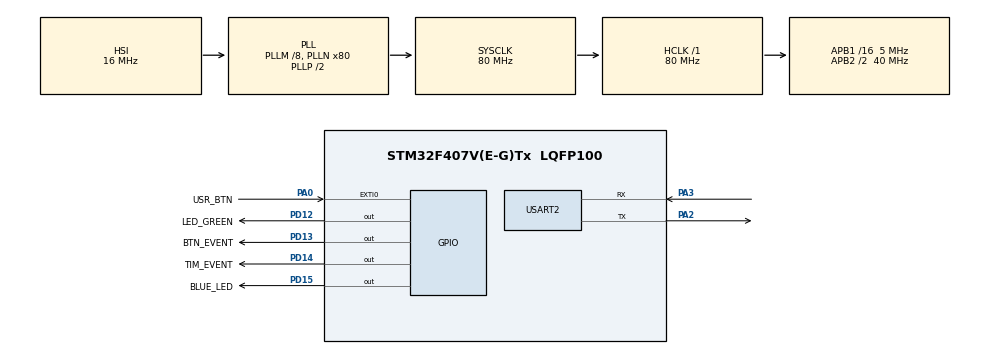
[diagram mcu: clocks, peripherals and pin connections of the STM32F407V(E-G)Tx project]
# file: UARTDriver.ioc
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FREERTOS.Tasks01=defaultTask,0,128,StartDefaultTask,Default,NULL,Dynamic,NULL,NULL
Mcu.Family=STM32F4
Mcu.Name=STM32F407V(E-G)Tx
Mcu.Package=LQFP100
NVIC.EXTI0_IRQn=true\:5\:0\:true\:false\:true\:false\:true\:true\:true
NVIC.PriorityGroup=NVIC_PRIORITYGROUP_4
NVIC.TIM6_DAC_IRQn=true\:5\:0\:false\:false\:true\:true\:true\:true\:true
NVIC.USART2_IRQn=true\:5\:0\:false\:false\:true\:true\:true\:true\:true
PA0-WKUP.GPIO_Label=USR_BTN
PA0-WKUP.Signal=GPXTI0
PA2.Mode=Asynchronous
PA2.Signal=USART2_TX
PA3.Mode=Asynchronous
PA3.Signal=USART2_RX
PD12.GPIO_Label=LED_GREEN
PD12.PinState=GPIO_PIN_SET
PD12.Signal=GPIO_Output
PD13.GPIO_Label=BTN_EVENT
PD13.Signal=GPIO_Output
PD14.GPIO_Label=TIM_EVENT
PD14.Signal=GPIO_Output
PD15.GPIO_Label=BLUE_LED
PD15.Signal=GPIO_Output
ProjectManager.HeapSize=0x200
ProjectManager.StackSize=0x400
ProjectManager.TargetToolchain=Makefile
RCC.48MHZClocksFreq_Value=22857142.85714286
RCC.AHBFreq_Value=80000000
RCC.APB1CLKDivider=RCC_HCLK_DIV16
RCC.APB1Freq_Value=5000000
RCC.APB1TimFreq_Value=10000000
RCC.APB2CLKDivider=RCC_HCLK_DIV2
RCC.APB2Freq_Value=40000000
RCC.APB2TimFreq_Value=80000000
RCC.CortexFreq_Value=80000000
RCC.HCLKFreq_Value=80000000
RCC.HSE_VALUE=8000000
RCC.HSI_VALUE=16000000
RCC.LSE_VALUE=32768
RCC.PLLM=8
RCC.PLLN=80
RCC.PLLQ=7
RCC.SYSCLKFreq_VALUE=80000000
RCC.SYSCLKSource=RCC_SYSCLKSOURCE_PLLCLK
RCC.VCOOutputFreq_Value=160000000
TIM6.AutoReloadPreload=TIM_AUTORELOAD_PRELOAD_ENABLE
TIM6.Period=4999
TIM6.Prescaler=9999
USART2.VirtualMode=VM_ASYNC
VP_FREERTOS_VS_CMSIS_V1.Mode=CMSIS_V1
VP_TIM6_VS_ClockSourceINT.Mode=Enable_Timer
board=STM32F407G-DISC1

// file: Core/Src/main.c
/* USER CODE BEGIN Header */
/**
  ******************************************************************************
  * @file           : main.c
  * @brief          : Main program body
  ******************************************************************************
  * @attention
  *
  * Copyright (c) 2023 STMicroelectronics.
  * All rights reserved.
  *
  * This software is licensed under terms that can be found in the LICENSE file
  * in the root directory of this software component.
  * If no LICENSE file comes with this software, it is provided AS-IS.
  *
  ******************************************************************************
  */
/* USER CODE END Header */
#include "main.h"
#include "cmsis_os.h"

/* USER CODE BEGIN Includes */
#include "Application.h"
/* USER CODE END Includes */

TIM_HandleTypeDef htim6;

UART_HandleTypeDef huart2;

osThreadId defaultTaskHandle;

void SystemClock_Config(void);
static void MX_GPIO_Init(void);
static void MX_TIM6_Init(void);
static void MX_USART2_UART_Init(void);
void StartDefaultTask(void const * argument);

/* USER CODE BEGIN 0 */
uint64_t delay = 100;
SemaphoreHandle_t xSemaphore = NULL;
SemaphoreHandle_t xTimerSemaphor = NULL;
SemaphoreHandle_t xUartSemaphore = NULL;
/* USER CODE END 0 */

int main(void)
{

  /* MCU Configuration--------------------------------------------------------*/

  /* Reset of all peripherals, Initializes the Flash interface and the Systick. */
  HAL_Init();

  /* Configure the system clock */
  SystemClock_Config();

  /* Initialize all configured peripherals */
  MX_GPIO_Init();
  MX_TIM6_Init();
  MX_USART2_UART_Init();

  /* USER CODE BEGIN RTOS_SEMAPHORES */
  /* add semaphores, ... */
  vSemaphoreCreateBinary(xSemaphore);
  vSemaphoreCreateBinary(xTimerSemaphor);
  vSemaphoreCreateBinary(xUartSemaphore);
  configASSERT(xSemaphore != NULL);
  /* USER CODE END RTOS_SEMAPHORES */

  /* Create the thread(s) */
  /* definition and creation of defaultTask */
  osThreadDef(defaultTask, StartDefaultTask, osPriorityNormal, 0, 128);
  defaultTaskHandle = osThreadCreate(osThread(defaultTask), NULL);

  /* USER CODE BEGIN RTOS_THREADS */
  /* add threads, ... */
  (void)xTaskCreate(Application_Init, "Start of App", configMINIMAL_STACK_SIZE, &delay, tskIDLE_PRIORITY, NULL);
  (void)xTaskCreate(Application_IntHandler, "ISR Handler", configMINIMAL_STACK_SIZE, NULL, tskIDLE_PRIORITY, NULL);
  (void)xTaskCreate(Application_UARTHandler, "UART Driver", configMINIMAL_STACK_SIZE, NULL, tskIDLE_PRIORITY, NULL);
  /* USER CODE END RTOS_THREADS */

  /* Start scheduler */
  osKernelStart();

  /* We should never get here as control is now taken by the scheduler */
  /* Infinite loop */
  while (1)
  {

  }
}

void SystemClock_Config(void)
{
  RCC_OscInitTypeDef RCC_OscInitStruct = {0};
  RCC_ClkInitTypeDef RCC_ClkInitStruct = {0};

  /** Configure the main internal regulator output voltage
  */
  __HAL_RCC_PWR_CLK_ENABLE();
  __HAL_PWR_VOLTAGESCALING_CONFIG(PWR_REGULATOR_VOLTAGE_SCALE1);

  /** Initializes the RCC Oscillators according to the specified parameters
  * in the RCC_OscInitTypeDef structure.
  */
  RCC_OscInitStruct.OscillatorType = RCC_OSCILLATORTYPE_HSI;
  RCC_OscInitStruct.HSIState = RCC_HSI_ON;
  RCC_OscInitStruct.HSICalibrationValue = RCC_HSICALIBRATION_DEFAULT;
  RCC_OscInitStruct.PLL.PLLState = RCC_PLL_ON;
  RCC_OscInitStruct.PLL.PLLSource = RCC_PLLSOURCE_HSI;
  RCC_OscInitStruct.PLL.PLLM = 8;
  RCC_OscInitStruct.PLL.PLLN = 80;
  RCC_OscInitStruct.PLL.PLLP = RCC_PLLP_DIV2;
  RCC_OscInitStruct.PLL.PLLQ = 7;
  if (HAL_RCC_OscConfig(&RCC_OscInitStruct) != HAL_OK)
  {
    Error_Handler();
  }

  /** Initializes the CPU, AHB and APB buses clocks
  */
  RCC_ClkInitStruct.ClockType = RCC_CLOCKTYPE_HCLK|RCC_CLOCKTYPE_SYSCLK
                              |RCC_CLOCKTYPE_PCLK1|RCC_CLOCKTYPE_PCLK2;
  RCC_ClkInitStruct.SYSCLKSource = RCC_SYSCLKSOURCE_PLLCLK;
  RCC_ClkInitStruct.AHBCLKDivider = RCC_SYSCLK_DIV1;
  RCC_ClkInitStruct.APB1CLKDivider = RCC_HCLK_DIV16;
  RCC_ClkInitStruct.APB2CLKDivider = RCC_HCLK_DIV2;

  if (HAL_RCC_ClockConfig(&RCC_ClkInitStruct, FLASH_LATENCY_2) != HAL_OK)
  {
    Error_Handler();
  }
}

static void MX_TIM6_Init(void)
{

  TIM_MasterConfigTypeDef sMasterConfig = {0};

  htim6.Instance = TIM6;
  htim6.Init.Prescaler = 9999;
  htim6.Init.CounterMode = TIM_COUNTERMODE_UP;
  htim6.Init.Period = 4999;
  htim6.Init.AutoReloadPreload = TIM_AUTORELOAD_PRELOAD_ENABLE;
  if (HAL_TIM_Base_Init(&htim6) != HAL_OK)
  {
    Error_Handler();
  }
  sMasterConfig.MasterOutputTrigger = TIM_TRGO_RESET;
  sMasterConfig.MasterSlaveMode = TIM_MASTERSLAVEMODE_DISABLE;
  if (HAL_TIMEx_MasterConfigSynchronization(&htim6, &sMasterConfig) != HAL_OK)
  {
    Error_Handler();
  }

}

static void MX_USART2_UART_Init(void)
{

  huart2.Instance = USART2;
  huart2.Init.BaudRate = 115200;
  huart2.Init.WordLength = UART_WORDLENGTH_8B;
  huart2.Init.StopBits = UART_STOPBITS_1;
  huart2.Init.Parity = UART_PARITY_NONE;
  huart2.Init.Mode = UART_MODE_TX_RX;
  huart2.Init.HwFlowCtl = UART_HWCONTROL_NONE;
  huart2.Init.OverSampling = UART_OVERSAMPLING_16;
  if (HAL_UART_Init(&huart2) != HAL_OK)
  {
    Error_Handler();
  }

}

static void MX_GPIO_Init(void)
{
  GPIO_InitTypeDef GPIO_InitStruct = {0};

  /* GPIO Ports Clock Enable */
  __HAL_RCC_GPIOA_CLK_ENABLE();
  __HAL_RCC_GPIOD_CLK_ENABLE();

  /*Configure GPIO pin Output Level */
  HAL_GPIO_WritePin(LED_GREEN_GPIO_Port, LED_GREEN_Pin, GPIO_PIN_SET);

  /*Configure GPIO pin Output Level */
  HAL_GPIO_WritePin(GPIOD, BTN_EVENT_Pin|TIM_EVENT_Pin|BLUE_LED_Pin, GPIO_PIN_RESET);

  /*Configure GPIO pin : USR_BTN_Pin */
  GPIO_InitStruct.Pin = USR_BTN_Pin;
  GPIO_InitStruct.Mode = GPIO_MODE_IT_RISING;
  GPIO_InitStruct.Pull = GPIO_NOPULL;
  HAL_GPIO_Init(USR_BTN_GPIO_Port, &GPIO_InitStruct);

  /*Configure GPIO pins : LED_GREEN_Pin BTN_EVENT_Pin TIM_EVENT_Pin BLUE_LED_Pin */
  GPIO_InitStruct.Pin = LED_GREEN_Pin|BTN_EVENT_Pin|TIM_EVENT_Pin|BLUE_LED_Pin;
  GPIO_InitStruct.Mode = GPIO_MODE_OUTPUT_PP;
  GPIO_InitStruct.Pull = GPIO_NOPULL;
  GPIO_InitStruct.Speed = GPIO_SPEED_FREQ_LOW;
  HAL_GPIO_Init(GPIOD, &GPIO_InitStruct);

  /* EXTI interrupt init*/
  HAL_NVIC_SetPriority(EXTI0_IRQn, 5, 0);
  HAL_NVIC_EnableIRQ(EXTI0_IRQn);

}

void StartDefaultTask(void const * argument)
{
  for(;;)
  {
    osDelay(1);
  }
}

void Error_Handler(void)
{
  __disable_irq();
  while (1)
  {
  }
}
